VERSION ""

NS_ :

BS_:

BU_:

BO_ 259 Sensor_board_1: 8 Vector__XXX
	SG_ Sensor1 : 7|16@0+ (1,0) [0|1000] "N/A" Vector__XXX
	SG_ Sensor5 : 23|16@0+ (1,0) [0|100000] "N/A" Vector__XXX

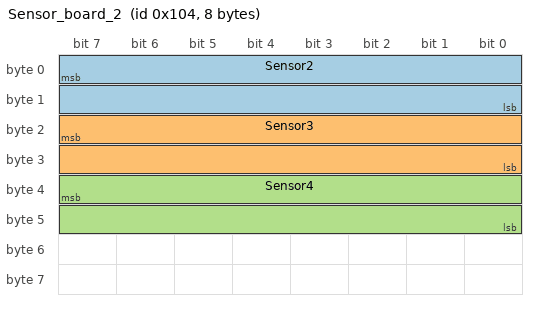
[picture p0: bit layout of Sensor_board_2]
BO_ 260 Sensor_board_2: 8 Vector__XXX
	SG_ Sensor2 : 7|16@0+ (1,0) [0|1000] "N/A" Vector__XXX
	SG_ Sensor3 : 23|16@0+ (0,0) [0|1000] "N/A" Vector__XXX
	SG_ Sensor4 : 39|16@0+ (0,0) [0|1000] "N/A" Vector__XXX

CM_ BO_ 259 "Sens1_data1";
CM_ BO_ 260 "Sens1_data2";
BA_DEF_ SG_  "SPN" INT 0 524287;
BA_DEF_ BO_  "VFrameFormat" ENUM  "StandardCAN","ExtendedCAN","reserved","J1939PG";
BA_DEF_  "DatabaseVersion" STRING ;
BA_DEF_  "BusType" STRING ;
BA_DEF_  "ProtocolType" STRING ;
BA_DEF_  "DatabaseCompiler" STRING ;
BA_DEF_DEF_  "SPN" 0;
BA_DEF_DEF_  "VFrameFormat" "J1939PG";
BA_DEF_DEF_  "DatabaseVersion" "DEMO PLUS";
BA_DEF_DEF_  "BusType" "";
BA_DEF_DEF_  "ProtocolType" "";
BA_DEF_DEF_  "DatabaseCompiler" "";
BA_ "ProtocolType" "J1939";
BA_ "BusType" "CAN";
BA_ "DatabaseCompiler" "CSS ELECTRONICS (WWW.CSSELECTRONICS.COM)";
BA_ "DatabaseVersion" "1.0.0";
BA_ "SPN" SG_ 2566844926 WheelBasedVehicleSpeed 84;
